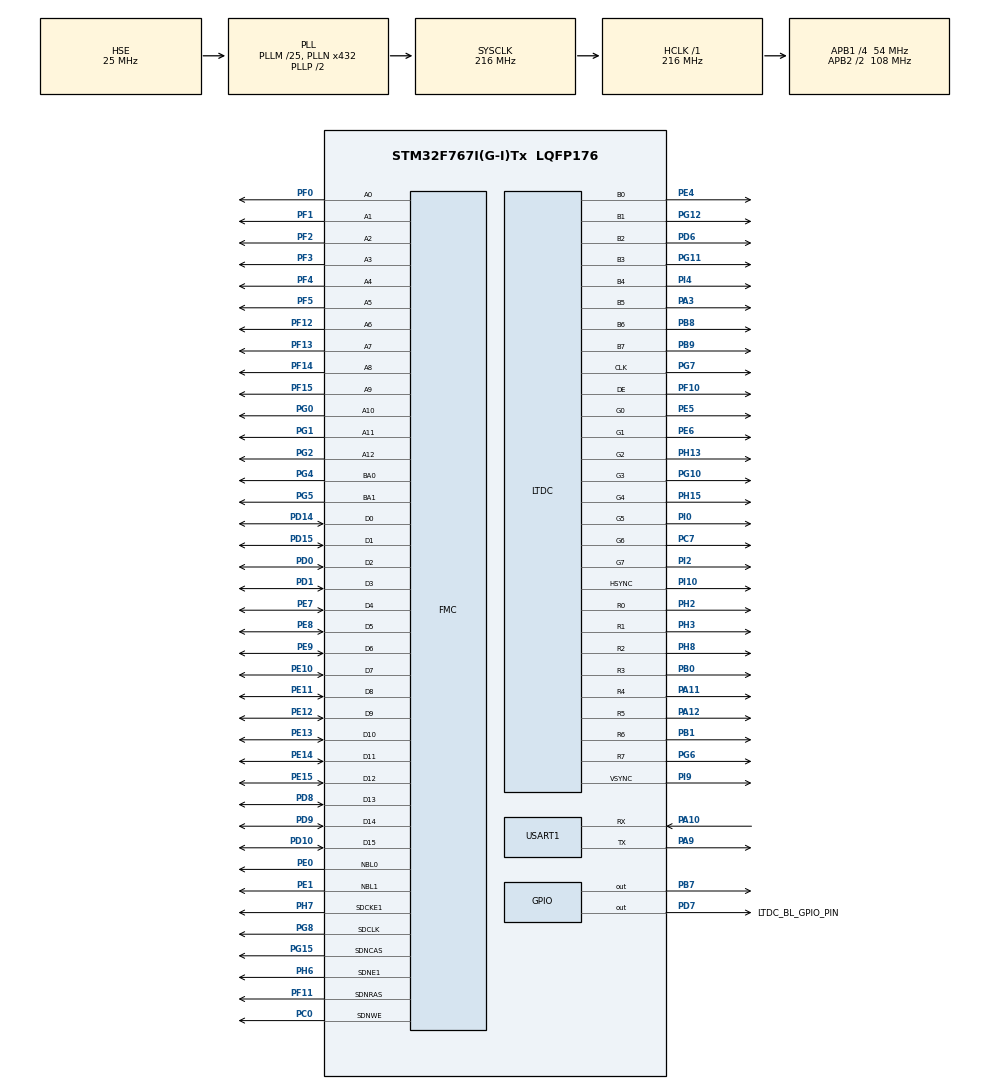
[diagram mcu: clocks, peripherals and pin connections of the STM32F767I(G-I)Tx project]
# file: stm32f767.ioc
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DMA2D.ColorMode=DMA2D_OUTPUT_RGB888
FMC.CASLatency2=FMC_SDRAM_CAS_LATENCY_3
FMC.ColumnBitsNumber2=FMC_SDRAM_COLUMN_BITS_NUM_9
FMC.ExitSelfRefreshDelay2=9
FMC.LoadToActiveDelay2=2
FMC.RCDDelay2=3
FMC.RPDelay1=3
FMC.RPDelay2=3
FMC.RowCycleDelay1=8
FMC.RowCycleDelay2=8
FMC.SDClockPeriod1=FMC_SDRAM_CLOCK_PERIOD_2
FMC.SDClockPeriod2=FMC_SDRAM_CLOCK_PERIOD_2
FMC.SelfRefreshTime2=6
FMC.WriteRecoveryTime2=3
LTDC.ActiveH=LCD_PIXEL_HEIGHT
LTDC.ActiveW=LCD_PIXEL_WIDTH
LTDC.Alpha_L0=255
LTDC.BlendingFactor1_L0=LTDC_BLENDING_FACTOR1_PAxCA
LTDC.BlendingFactor2_L0=LTDC_BLENDING_FACTOR2_PAxCA
LTDC.FBStartAdress_L0=LCD_FB_START_ADDRESS
LTDC.HBP=46
LTDC.HFP=22
LTDC.HSync=1
LTDC.ImageHeight_L0=LCD_PIXEL_HEIGHT
LTDC.ImageWidth_L0=LCD_PIXEL_WIDTH
LTDC.Layers=0
LTDC.PixelFormat_L0=LTDC_PIXEL_FORMAT_RGB888
LTDC.VBP=23
LTDC.VFP=22
LTDC.VSync=1
LTDC.WindowX1_L0=LCD_PIXEL_WIDTH
LTDC.WindowY1_L0=LCD_PIXEL_HEIGHT
Mcu.Family=STM32F7
Mcu.Name=STM32F767I(G-I)Tx
Mcu.Package=LQFP176
Mcu.UserConstants=LCD_FB_START_ADDRESS,0xD0000000;LCD_PIXEL_WIDTH,800;LCD_PIXEL_HEIGHT,480
NVIC.LTDC_IRQn=true\:0\:0\:false\:false\:true\:true\:true
NVIC.PriorityGroup=NVIC_PRIORITYGROUP_4
PA10.Mode=Asynchronous
PA10.Signal=USART1_RX
PA11.GPIO_PuPd=GPIO_PULLUP
PA11.GPIO_Speed=GPIO_SPEED_FREQ_HIGH
PA11.Mode=RGB888
PA11.Signal=LTDC_R4
PA12.GPIO_PuPd=GPIO_PULLUP
PA12.GPIO_Speed=GPIO_SPEED_FREQ_HIGH
PA12.Mode=RGB888
PA12.Signal=LTDC_R5
PA13.Mode=Serial_Wire
PA13.Signal=SYS_JTMS-SWDIO
PA14.Mode=Serial_Wire
PA14.Signal=SYS_JTCK-SWCLK
PA3.GPIO_PuPd=GPIO_PULLUP
PA3.GPIO_Speed=GPIO_SPEED_FREQ_HIGH
PA3.Mode=RGB888
PA3.Signal=LTDC_B5
PA9.Mode=Asynchronous
PA9.Signal=USART1_TX
PB0.GPIO_PuPd=GPIO_PULLUP
PB0.GPIO_Speed=GPIO_SPEED_FREQ_HIGH
PB0.Mode=RGB888
PB0.Signal=LTDC_R3
PB1.GPIO_PuPd=GPIO_PULLUP
PB1.GPIO_Speed=GPIO_SPEED_FREQ_HIGH
PB1.Mode=RGB888
PB1.Signal=LTDC_R6
PB7.Signal=GPIO_Output
PB8.GPIO_PuPd=GPIO_PULLUP
PB8.GPIO_Speed=GPIO_SPEED_FREQ_HIGH
PB8.Mode=RGB888
PB8.Signal=LTDC_B6
PB9.GPIO_PuPd=GPIO_PULLUP
PB9.GPIO_Speed=GPIO_SPEED_FREQ_HIGH
PB9.Mode=RGB888
PB9.Signal=LTDC_B7
PC0.Signal=FMC_SDNWE
PC7.GPIO_PuPd=GPIO_PULLUP
PC7.GPIO_Speed=GPIO_SPEED_FREQ_HIGH
PC7.Mode=RGB888
PC7.Signal=LTDC_G6
PD0.Signal=FMC_D2_DA2
PD1.Signal=FMC_D3_DA3
PD10.Signal=FMC_D15_DA15
PD14.Signal=FMC_D0_DA0
PD15.Signal=FMC_D1_DA1
PD6.GPIO_PuPd=GPIO_PULLUP
PD6.GPIO_Speed=GPIO_SPEED_FREQ_HIGH
PD6.Mode=RGB888
PD6.Signal=LTDC_B2
PD7.GPIO_Label=LTDC_BL_GPIO_PIN
PD7.Signal=GPIO_Output
PD8.Signal=FMC_D13_DA13
PD9.Signal=FMC_D14_DA14
PE0.Signal=FMC_NBL0
PE1.Signal=FMC_NBL1
PE10.Signal=FMC_D7_DA7
PE11.Signal=FMC_D8_DA8
PE12.Signal=FMC_D9_DA9
PE13.Signal=FMC_D10_DA10
PE14.Signal=FMC_D11_DA11
PE15.Signal=FMC_D12_DA12
PE4.GPIO_PuPd=GPIO_PULLUP
PE4.GPIO_Speed=GPIO_SPEED_FREQ_HIGH
PE4.Mode=RGB888
PE4.Signal=LTDC_B0
PE5.GPIO_PuPd=GPIO_PULLUP
PE5.GPIO_Speed=GPIO_SPEED_FREQ_HIGH
PE5.Mode=RGB888
PE5.Signal=LTDC_G0
PE6.GPIO_PuPd=GPIO_PULLUP
PE6.GPIO_Speed=GPIO_SPEED_FREQ_HIGH
PE6.Mode=RGB888
PE6.Signal=LTDC_G1
PE7.Signal=FMC_D4_DA4
PE8.Signal=FMC_D5_DA5
PE9.Signal=FMC_D6_DA6
PF0.Signal=FMC_A0
PF1.Signal=FMC_A1
PF10.GPIO_PuPd=GPIO_PULLUP
PF10.GPIO_Speed=GPIO_SPEED_FREQ_HIGH
PF10.Mode=RGB888
PF10.Signal=LTDC_DE
PF11.Signal=FMC_SDNRAS
PF12.Signal=FMC_A6
PF13.Signal=FMC_A7
PF14.Signal=FMC_A8
PF15.Signal=FMC_A9
PF2.Signal=FMC_A2
PF3.Signal=FMC_A3
PF4.Signal=FMC_A4
PF5.Signal=FMC_A5
PG0.Signal=FMC_A10
PG1.Signal=FMC_A11
PG10.GPIO_PuPd=GPIO_PULLUP
PG10.GPIO_Speed=GPIO_SPEED_FREQ_HIGH
PG10.Mode=RGB888
PG10.Signal=LTDC_G3
PG11.GPIO_PuPd=GPIO_PULLUP
PG11.GPIO_Speed=GPIO_SPEED_FREQ_HIGH
PG11.Mode=RGB888
PG11.Signal=LTDC_B3
PG12.GPIO_PuPd=GPIO_PULLUP
PG12.GPIO_Speed=GPIO_SPEED_FREQ_HIGH
PG12.Mode=RGB888
PG12.Signal=LTDC_B1
PG15.Signal=FMC_SDNCAS
PG2.Signal=FMC_A12
PG4.Signal=FMC_A14_BA0
PG5.Signal=FMC_A15_BA1
PG6.GPIO_PuPd=GPIO_PULLUP
PG6.GPIO_Speed=GPIO_SPEED_FREQ_HIGH
PG6.Mode=RGB888
PG6.Signal=LTDC_R7
PG7.GPIO_PuPd=GPIO_PULLUP
PG7.GPIO_Speed=GPIO_SPEED_FREQ_HIGH
PG7.Mode=RGB888
PG7.Signal=LTDC_CLK
PG8.Signal=FMC_SDCLK
PH0/OSC_IN.Mode=HSE-External-Oscillator
PH0/OSC_IN.Signal=RCC_OSC_IN
PH1/OSC_OUT.Mode=HSE-External-Oscillator
PH1/OSC_OUT.Signal=RCC_OSC_OUT
PH13.GPIO_PuPd=GPIO_PULLUP
PH13.GPIO_Speed=GPIO_SPEED_FREQ_HIGH
PH13.Mode=RGB888
PH13.Signal=LTDC_G2
PH15.GPIO_PuPd=GPIO_PULLUP
PH15.GPIO_Speed=GPIO_SPEED_FREQ_HIGH
PH15.Mode=RGB888
PH15.Signal=LTDC_G4
PH2.GPIO_PuPd=GPIO_PULLUP
PH2.GPIO_Speed=GPIO_SPEED_FREQ_HIGH
PH2.Mode=RGB888
PH2.Signal=LTDC_R0
PH3.GPIO_PuPd=GPIO_PULLUP
PH3.GPIO_Speed=GPIO_SPEED_FREQ_HIGH
PH3.Mode=RGB888
PH3.Signal=LTDC_R1
PH6.Mode=SdramChipSelect2_2
PH6.Signal=FMC_SDNE1
PH7.Mode=SdramChipSelect2_2
PH7.Signal=FMC_SDCKE1
PH8.GPIO_PuPd=GPIO_PULLUP
PH8.GPIO_Speed=GPIO_SPEED_FREQ_HIGH
PH8.Mode=RGB888
PH8.Signal=LTDC_R2
PI0.GPIO_PuPd=GPIO_PULLUP
PI0.GPIO_Speed=GPIO_SPEED_FREQ_HIGH
PI0.Mode=RGB888
PI0.Signal=LTDC_G5
PI10.GPIO_PuPd=GPIO_PULLUP
PI10.GPIO_Speed=GPIO_SPEED_FREQ_HIGH
PI10.Mode=RGB888
PI10.Signal=LTDC_HSYNC
PI2.GPIO_PuPd=GPIO_PULLUP
PI2.GPIO_Speed=GPIO_SPEED_FREQ_HIGH
PI2.Mode=RGB888
PI2.Signal=LTDC_G7
PI4.GPIO_PuPd=GPIO_PULLUP
PI4.GPIO_Speed=GPIO_SPEED_FREQ_HIGH
PI4.Mode=RGB888
PI4.Signal=LTDC_B4
PI9.GPIO_PuPd=GPIO_PULLUP
PI9.GPIO_Speed=GPIO_SPEED_FREQ_HIGH
PI9.Mode=RGB888
PI9.Signal=LTDC_VSYNC
ProjectManager.HeapSize=0x200
ProjectManager.StackSize=0x400
ProjectManager.TargetToolchain=Makefile
RCC.AHBFreq_Value=216000000
RCC.APB1CLKDivider=RCC_HCLK_DIV4
RCC.APB1Freq_Value=54000000
RCC.APB1TimFreq_Value=108000000
RCC.APB2CLKDivider=RCC_HCLK_DIV2
RCC.APB2Freq_Value=108000000
RCC.APB2TimFreq_Value=216000000
RCC.CortexFreq_Value=216000000
RCC.HCLKFreq_Value=216000000
RCC.HSE_VALUE=25000000
RCC.HSI_VALUE=16000000
RCC.LSE_VALUE=32768
RCC.PLLM=25
RCC.PLLN=432
RCC.PLLSAIRDiv=RCC_PLLSAIDIVR_4
RCC.PLLSourceVirtual=RCC_PLLSOURCE_HSE
RCC.SYSCLKFreq_VALUE=216000000
RCC.SYSCLKSource=RCC_SYSCLKSOURCE_PLLCLK
RCC.USBFreq_Value=216000000
RCC.VCOOutputFreq_Value=432000000
SH.FMC_A0.0=FMC_A0,13b-sda2
SH.FMC_A1.0=FMC_A1,13b-sda2
SH.FMC_A10.0=FMC_A10,13b-sda2
SH.FMC_A11.0=FMC_A11,13b-sda2
SH.FMC_A12.0=FMC_A12,13b-sda2
SH.FMC_A14_BA0.0=FMC_BA0,FourSdramBanks2
SH.FMC_A15_BA1.0=FMC_BA1,FourSdramBanks2
SH.FMC_A2.0=FMC_A2,13b-sda2
SH.FMC_A3.0=FMC_A3,13b-sda2
SH.FMC_A4.0=FMC_A4,13b-sda2
SH.FMC_A5.0=FMC_A5,13b-sda2
SH.FMC_A6.0=FMC_A6,13b-sda2
SH.FMC_A7.0=FMC_A7,13b-sda2
SH.FMC_A8.0=FMC_A8,13b-sda2
SH.FMC_A9.0=FMC_A9,13b-sda2
SH.FMC_D0_DA0.0=FMC_D0,sd-16b-d2
SH.FMC_D10_DA10.0=FMC_D10,sd-16b-d2
SH.FMC_D11_DA11.0=FMC_D11,sd-16b-d2
SH.FMC_D12_DA12.0=FMC_D12,sd-16b-d2
SH.FMC_D13_DA13.0=FMC_D13,sd-16b-d2
SH.FMC_D14_DA14.0=FMC_D14,sd-16b-d2
SH.FMC_D15_DA15.0=FMC_D15,sd-16b-d2
SH.FMC_D1_DA1.0=FMC_D1,sd-16b-d2
SH.FMC_D2_DA2.0=FMC_D2,sd-16b-d2
SH.FMC_D3_DA3.0=FMC_D3,sd-16b-d2
SH.FMC_D4_DA4.0=FMC_D4,sd-16b-d2
SH.FMC_D5_DA5.0=FMC_D5,sd-16b-d2
SH.FMC_D6_DA6.0=FMC_D6,sd-16b-d2
SH.FMC_D7_DA7.0=FMC_D7,sd-16b-d2
SH.FMC_D8_DA8.0=FMC_D8,sd-16b-d2
SH.FMC_D9_DA9.0=FMC_D9,sd-16b-d2
SH.FMC_NBL0.0=FMC_NBL0,Sd2ByteEnable2
SH.FMC_NBL1.0=FMC_NBL1,Sd2ByteEnable2
SH.FMC_SDCLK.0=FMC_SDCLK,13b-sda2
SH.FMC_SDNCAS.0=FMC_SDNCAS,13b-sda2
SH.FMC_SDNRAS.0=FMC_SDNRAS,13b-sda2
SH.FMC_SDNWE.0=FMC_SDNWE,13b-sda2
TIM3.AutoReloadPreload=TIM_AUTORELOAD_PRELOAD_ENABLE
TIM3.Period=10800-1
TIM3.Prescaler=5000-1
USART1.VirtualMode-Asynchronous=VM_ASYNC
VP_DMA2D_VS_DMA2D.Mode=DMA2D_Activate
VP_TIM3_VS_ClockSourceINT.Mode=Internal
board=custom

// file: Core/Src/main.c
/* USER CODE BEGIN Header */
/**
  ******************************************************************************
  * @file           : main.c
  * @brief          : Main program body
  ******************************************************************************
  * @attention
  *
  * <h2><center>&copy; Copyright (c) 2022 STMicroelectronics.
  * All rights reserved.</center></h2>
  *
  * This software component is licensed by ST under BSD 3-Clause license,
  * the "License"; You may not use this file except in compliance with the
  * License. You may obtain a copy of the License at:
  *                        opensource.org/licenses/BSD-3-Clause
  *
  ******************************************************************************
  */
/* USER CODE END Header */
#include "main.h"
#include "dma2d.h"
#include "ltdc.h"
#include "tim.h"
#include "usart.h"
#include "gpio.h"
#include "fmc.h"

/* USER CODE BEGIN Includes */
#include "lcd_display.h"
/* USER CODE END Includes */

void SystemClock_Config(void);

/* USER CODE BEGIN 0 */
void rock_lcd_test()
{
  printf("lcd ok\n");

  /* LCD 第一层初始化 */
  LCD_LayerInit(0, LCD_FB_START_ADDRESS,ARGB8888);

  LCD_DisplayOn();

  /* 选择LCD第一层 */
  LCD_SelectLayer(0);

  /* 第一层清屏，显示全黑 */
  LCD_Clear(LCD_COLOR_BLACK);

  /* 选择LCD第二层 */
  LCD_SelectLayer(1);

  /* 第二层清屏，显示全黑 */
  LCD_Clear(LCD_COLOR_TRANSPARENT);

  LCD_SelectLayer(0);

  LCD_SetColors(LCD_COLOR_RED,LCD_COLOR_BLACK);
  LCD_DrawLine(50,250,750,250);

  LCD_SetColors(LCD_COLOR_RED,LCD_COLOR_BLACK);
  LCD_FillRect(200,250,200,100);

  LCD_SetColors(LCD_COLOR_GREEN,LCD_COLOR_GREEN);
  LCD_DrawCircle(200,350,50);
}
/* USER CODE END 0 */

int main(void)
{

  /* MCU Configuration--------------------------------------------------------*/

  /* Reset of all peripherals, Initializes the Flash interface and the Systick. */
  HAL_Init();

  /* Configure the system clock */
  SystemClock_Config();

  /* Initialize all configured peripherals */
  MX_GPIO_Init();
  MX_TIM3_Init();
  MX_USART1_UART_Init();
  MX_FMC_Init();
  MX_LTDC_Init();
  MX_DMA2D_Init();
  /* USER CODE BEGIN 2 */
  rock_lcd_test();
  /* USER CODE END 2 */

  /* Infinite loop */
  while (1)
  {

  }
}

void SystemClock_Config(void)
{
  RCC_OscInitTypeDef RCC_OscInitStruct = {0};
  RCC_ClkInitTypeDef RCC_ClkInitStruct = {0};
  RCC_PeriphCLKInitTypeDef PeriphClkInitStruct = {0};

  /** Configure the main internal regulator output voltage
  */
  __HAL_RCC_PWR_CLK_ENABLE();
  __HAL_PWR_VOLTAGESCALING_CONFIG(PWR_REGULATOR_VOLTAGE_SCALE1);
  /** Initializes the RCC Oscillators according to the specified parameters
  * in the RCC_OscInitTypeDef structure.
  */
  RCC_OscInitStruct.OscillatorType = RCC_OSCILLATORTYPE_HSE;
  RCC_OscInitStruct.HSEState = RCC_HSE_ON;
  RCC_OscInitStruct.PLL.PLLState = RCC_PLL_ON;
  RCC_OscInitStruct.PLL.PLLSource = RCC_PLLSOURCE_HSE;
  RCC_OscInitStruct.PLL.PLLM = 25;
  RCC_OscInitStruct.PLL.PLLN = 432;
  RCC_OscInitStruct.PLL.PLLP = RCC_PLLP_DIV2;
  RCC_OscInitStruct.PLL.PLLQ = 2;
  RCC_OscInitStruct.PLL.PLLR = 2;
  if (HAL_RCC_OscConfig(&RCC_OscInitStruct) != HAL_OK)
  {
    Error_Handler();
  }
  /** Activate the Over-Drive mode
  */
  if (HAL_PWREx_EnableOverDrive() != HAL_OK)
  {
    Error_Handler();
  }
  /** Initializes the CPU, AHB and APB buses clocks
  */
  RCC_ClkInitStruct.ClockType = RCC_CLOCKTYPE_HCLK|RCC_CLOCKTYPE_SYSCLK
                              |RCC_CLOCKTYPE_PCLK1|RCC_CLOCKTYPE_PCLK2;
  RCC_ClkInitStruct.SYSCLKSource = RCC_SYSCLKSOURCE_PLLCLK;
  RCC_ClkInitStruct.AHBCLKDivider = RCC_SYSCLK_DIV1;
  RCC_ClkInitStruct.APB1CLKDivider = RCC_HCLK_DIV4;
  RCC_ClkInitStruct.APB2CLKDivider = RCC_HCLK_DIV2;

  if (HAL_RCC_ClockConfig(&RCC_ClkInitStruct, FLASH_LATENCY_7) != HAL_OK)
  {
    Error_Handler();
  }
  PeriphClkInitStruct.PeriphClockSelection = RCC_PERIPHCLK_LTDC|RCC_PERIPHCLK_USART1;
  PeriphClkInitStruct.PLLSAI.PLLSAIN = 192;
  PeriphClkInitStruct.PLLSAI.PLLSAIR = 2;
  PeriphClkInitStruct.PLLSAI.PLLSAIQ = 2;
  PeriphClkInitStruct.PLLSAI.PLLSAIP = RCC_PLLSAIP_DIV2;
  PeriphClkInitStruct.PLLSAIDivQ = 1;
  PeriphClkInitStruct.PLLSAIDivR = RCC_PLLSAIDIVR_4;
  PeriphClkInitStruct.Usart1ClockSelection = RCC_USART1CLKSOURCE_PCLK2;
  if (HAL_RCCEx_PeriphCLKConfig(&PeriphClkInitStruct) != HAL_OK)
  {
    Error_Handler();
  }
}

void Error_Handler(void)
{
  __disable_irq();
  while (1)
  {
  }
}

/************************ (C) COPYRIGHT STMicroelectronics *****END OF FILE****/
